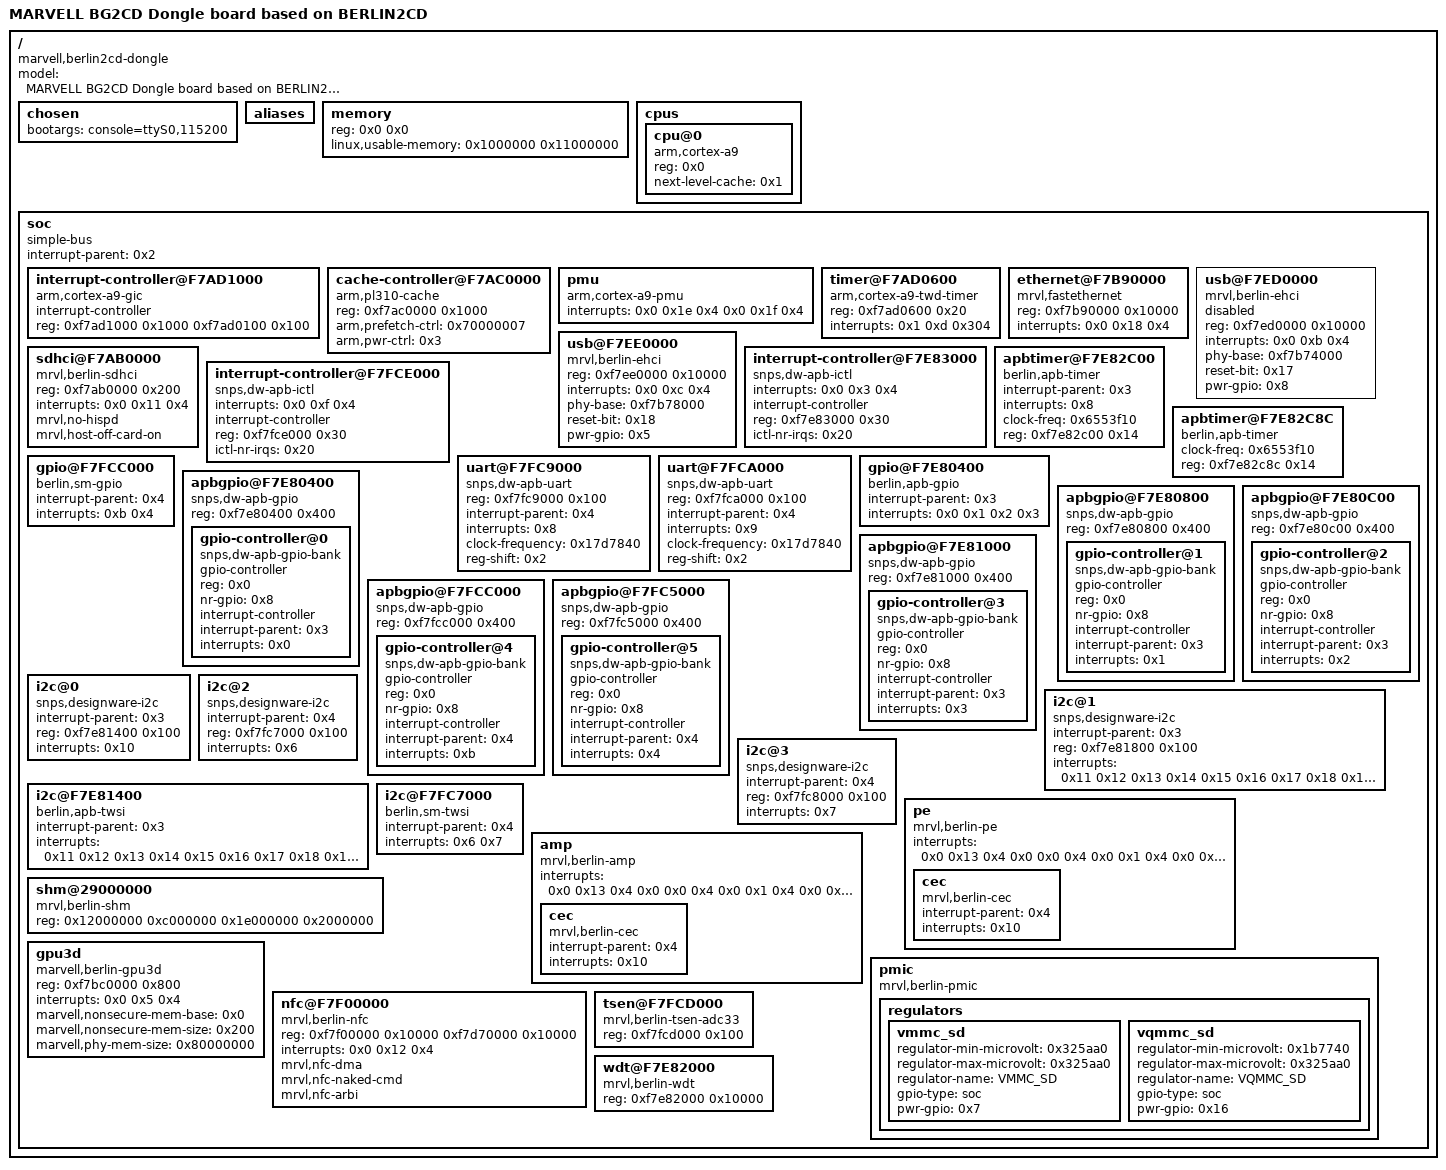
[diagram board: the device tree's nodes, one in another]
/dts-v1/;

/ {
	#address-cells = <0x1>;
	#size-cells = <0x1>;
	model = "MARVELL BG2CD Dongle board based on BERLIN2CD";
	compatible = "marvell,berlin2cd-dongle", "marvell,berlin2cd";

	chosen {
		bootargs = "console=ttyS0,115200";
	};

	aliases {
	};

	memory {
		device_type = "memory";
		reg = <0x0 0x0>;
		linux,usable-memory = <0x1000000 0x11000000>;
	};

	cpus {
		#address-cells = <0x1>;
		#size-cells = <0x0>;

		cpu@0 {
			device_type = "cpu";
			compatible = "arm,cortex-a9";
			reg = <0x0>;
			next-level-cache = <0x1>;
		};
	};

	soc {
		#address-cells = <0x1>;
		#size-cells = <0x1>;
		compatible = "simple-bus";
		interrupt-parent = <0x2>;
		ranges;

		interrupt-controller@F7AD1000 {
			compatible = "arm,cortex-a9-gic";
			#interrupt-cells = <0x3>;
			interrupt-controller;
			reg = <0xf7ad1000 0x1000 0xf7ad0100 0x100>;
			linux,phandle = <0x2>;
			phandle = <0x2>;
		};

		cache-controller@F7AC0000 {
			compatible = "arm,pl310-cache";
			reg = <0xf7ac0000 0x1000>;
			arm,prefetch-ctrl = <0x70000007>;
			arm,pwr-ctrl = <0x3>;
			linux,phandle = <0x1>;
			phandle = <0x1>;
		};

		pmu {
			compatible = "arm,cortex-a9-pmu";
			interrupts = <0x0 0x1e 0x4 0x0 0x1f 0x4>;
		};

		timer@F7AD0600 {
			compatible = "arm,cortex-a9-twd-timer";
			reg = <0xf7ad0600 0x20>;
			interrupts = <0x1 0xd 0x304>;
		};

		ethernet@F7B90000 {
			compatible = "mrvl,fastethernet";
			reg = <0xf7b90000 0x10000>;
			interrupts = <0x0 0x18 0x4>;
		};

		usb@F7ED0000 {
			compatible = "mrvl,berlin-ehci";
			reg = <0xf7ed0000 0x10000>;
			interrupts = <0x0 0xb 0x4>;
			phy-base = <0xf7b74000>;
			reset-bit = <0x17>;
			pwr-gpio = <0x8>;
			status = "disable";
		};

		usb@F7EE0000 {
			compatible = "mrvl,berlin-ehci";
			reg = <0xf7ee0000 0x10000>;
			interrupts = <0x0 0xc 0x4>;
			phy-base = <0xf7b78000>;
			reset-bit = <0x18>;
			pwr-gpio = <0x5>;
		};

		sdhci@F7AB0000 {
			compatible = "mrvl,berlin-sdhci";
			reg = <0xf7ab0000 0x200>;
			interrupts = <0x0 0x11 0x4>;
			mrvl,no-hispd;
			mrvl,host-off-card-on;
		};

		interrupt-controller@F7E83000 {
			compatible = "snps,dw-apb-ictl";
			interrupts = <0x0 0x3 0x4>;
			interrupt-controller;
			#interrupt-cells = <0x1>;
			reg = <0xf7e83000 0x30>;
			ictl-nr-irqs = <0x20>;
			linux,phandle = <0x3>;
			phandle = <0x3>;
		};

		interrupt-controller@F7FCE000 {
			compatible = "snps,dw-apb-ictl";
			interrupts = <0x0 0xf 0x4>;
			interrupt-controller;
			#interrupt-cells = <0x1>;
			reg = <0xf7fce000 0x30>;
			ictl-nr-irqs = <0x20>;
			linux,phandle = <0x4>;
			phandle = <0x4>;
		};

		apbtimer@F7E82C00 {
			compatible = "berlin,apb-timer";
			interrupt-parent = <0x3>;
			interrupts = <0x8>;
			clock-freq = <0x6553f10>;
			reg = <0xf7e82c00 0x14>;
		};

		apbtimer@F7E82C8C {
			compatible = "berlin,apb-timer";
			clock-freq = <0x6553f10>;
			reg = <0xf7e82c8c 0x14>;
		};

		uart@F7FC9000 {
			compatible = "snps,dw-apb-uart";
			reg = <0xf7fc9000 0x100>;
			interrupt-parent = <0x4>;
			interrupts = <0x8>;
			clock-frequency = <0x17d7840>;
			reg-shift = <0x2>;
		};

		uart@F7FCA000 {
			compatible = "snps,dw-apb-uart";
			reg = <0xf7fca000 0x100>;
			interrupt-parent = <0x4>;
			interrupts = <0x9>;
			clock-frequency = <0x17d7840>;
			reg-shift = <0x2>;
		};

		gpio@F7E80400 {
			compatible = "berlin,apb-gpio";
			interrupt-parent = <0x3>;
			interrupts = <0x0 0x1 0x2 0x3>;
		};

		gpio@F7FCC000 {
			compatible = "berlin,sm-gpio";
			interrupt-parent = <0x4>;
			interrupts = <0xb 0x4>;
		};

		apbgpio@F7E80400 {
			compatible = "snps,dw-apb-gpio";
			reg = <0xf7e80400 0x400>;
			#address-cells = <0x1>;
			#size-cells = <0x0>;

			gpio-controller@0 {
				compatible = "snps,dw-apb-gpio-bank";
				gpio-controller;
				reg = <0x0>;
				#gpio-cells = <0x2>;
				nr-gpio = <0x8>;
				interrupt-controller;
				#interrupt-cells = <0x2>;
				interrupt-parent = <0x3>;
				interrupts = <0x0>;
			};
		};

		apbgpio@F7E80800 {
			compatible = "snps,dw-apb-gpio";
			reg = <0xf7e80800 0x400>;
			#address-cells = <0x1>;
			#size-cells = <0x0>;

			gpio-controller@1 {
				compatible = "snps,dw-apb-gpio-bank";
				gpio-controller;
				reg = <0x0>;
				#gpio-cells = <0x2>;
				nr-gpio = <0x8>;
				interrupt-controller;
				#interrupt-cells = <0x2>;
				interrupt-parent = <0x3>;
				interrupts = <0x1>;
			};
		};

		apbgpio@F7E80C00 {
			compatible = "snps,dw-apb-gpio";
			reg = <0xf7e80c00 0x400>;
			#address-cells = <0x1>;
			#size-cells = <0x0>;

			gpio-controller@2 {
				compatible = "snps,dw-apb-gpio-bank";
				gpio-controller;
				reg = <0x0>;
				#gpio-cells = <0x2>;
				nr-gpio = <0x8>;
				interrupt-controller;
				#interrupt-cells = <0x2>;
				interrupt-parent = <0x3>;
				interrupts = <0x2>;
			};
		};

		apbgpio@F7E81000 {
			compatible = "snps,dw-apb-gpio";
			reg = <0xf7e81000 0x400>;
			#address-cells = <0x1>;
			#size-cells = <0x0>;

			gpio-controller@3 {
				compatible = "snps,dw-apb-gpio-bank";
				gpio-controller;
				reg = <0x0>;
				#gpio-cells = <0x2>;
				nr-gpio = <0x8>;
				interrupt-controller;
				#interrupt-cells = <0x2>;
				interrupt-parent = <0x3>;
				interrupts = <0x3>;
			};
		};

		apbgpio@F7FCC000 {
			compatible = "snps,dw-apb-gpio";
			reg = <0xf7fcc000 0x400>;
			#address-cells = <0x1>;
			#size-cells = <0x0>;

			gpio-controller@4 {
				compatible = "snps,dw-apb-gpio-bank";
				gpio-controller;
				reg = <0x0>;
				#gpio-cells = <0x2>;
				nr-gpio = <0x8>;
				interrupt-controller;
				#interrupt-cells = <0x2>;
				interrupt-parent = <0x4>;
				interrupts = <0xb>;
			};
		};

		apbgpio@F7FC5000 {
			compatible = "snps,dw-apb-gpio";
			reg = <0xf7fc5000 0x400>;
			#address-cells = <0x1>;
			#size-cells = <0x0>;

			gpio-controller@5 {
				compatible = "snps,dw-apb-gpio-bank";
				gpio-controller;
				reg = <0x0>;
				#gpio-cells = <0x2>;
				nr-gpio = <0x8>;
				interrupt-controller;
				#interrupt-cells = <0x2>;
				interrupt-parent = <0x4>;
				interrupts = <0x4>;
			};
		};

		i2c@0 {
			compatible = "snps,designware-i2c";
			interrupt-parent = <0x3>;
			reg = <0xf7e81400 0x100>;
			interrupts = <0x10>;
		};

		i2c@1 {
			compatible = "snps,designware-i2c";
			interrupt-parent = <0x3>;
			reg = <0xf7e81800 0x100>;
			interrupts = <0x11 0x12 0x13 0x14 0x15 0x16 0x17 0x18 0x19 0x1a 0x1b 0x1c>;
		};

		i2c@2 {
			compatible = "snps,designware-i2c";
			interrupt-parent = <0x4>;
			reg = <0xf7fc7000 0x100>;
			interrupts = <0x6>;
		};

		i2c@3 {
			compatible = "snps,designware-i2c";
			interrupt-parent = <0x4>;
			reg = <0xf7fc8000 0x100>;
			interrupts = <0x7>;
		};

		i2c@F7E81400 {
			compatible = "berlin,apb-twsi";
			interrupt-parent = <0x3>;
			interrupts = <0x11 0x12 0x13 0x14 0x15 0x16 0x17 0x18 0x19 0x1a 0x1b 0x1c 0x10>;
		};

		i2c@F7FC7000 {
			compatible = "berlin,sm-twsi";
			interrupt-parent = <0x4>;
			interrupts = <0x6 0x7>;
		};

		pe {
			compatible = "mrvl,berlin-pe";
			interrupts = <0x0 0x13 0x4 0x0 0x0 0x4 0x0 0x1 0x4 0x0 0x19 0x4 0x0 0x2 0x4>;

			cec {
				compatible = "mrvl,berlin-cec";
				interrupt-parent = <0x4>;
				interrupts = <0x10>;
			};
		};

		amp {
			compatible = "mrvl,berlin-amp";
			interrupts = <0x0 0x13 0x4 0x0 0x0 0x4 0x0 0x1 0x4 0x0 0x19 0x4 0x0 0x2 0x4>;

			cec {
				compatible = "mrvl,berlin-cec";
				interrupt-parent = <0x4>;
				interrupts = <0x10>;
			};
		};

		shm@29000000 {
			compatible = "mrvl,berlin-shm";
			reg = <0x12000000 0xc000000 0x1e000000 0x2000000>;
		};

		gpu3d {
			compatible = "marvell,berlin-gpu3d";
			reg = <0xf7bc0000 0x800>;
			interrupts = <0x0 0x5 0x4>;
			marvell,nonsecure-mem-base = <0x0>;
			marvell,nonsecure-mem-size = <0x200>;
			marvell,phy-mem-size = <0x80000000>;
		};

		pmic {
			compatible = "mrvl,berlin-pmic";

			regulators {

				vmmc_sd {
					regulator-min-microvolt = <0x325aa0>;
					regulator-max-microvolt = <0x325aa0>;
					regulator-name = "VMMC_SD";
					gpio-type = "soc";
					pwr-gpio = <0x7>;
				};

				vqmmc_sd {
					regulator-min-microvolt = <0x1b7740>;
					regulator-max-microvolt = <0x325aa0>;
					regulator-name = "VQMMC_SD";
					gpio-type = "soc";
					pwr-gpio = <0x16>;
				};
			};
		};

		nfc@F7F00000 {
			compatible = "mrvl,berlin-nfc";
			reg = <0xf7f00000 0x10000 0xf7d70000 0x10000>;
			interrupts = <0x0 0x12 0x4>;
			mrvl,nfc-dma;
			mrvl,nfc-naked-cmd;
			mrvl,nfc-arbi;
		};

		tsen@F7FCD000 {
			compatible = "mrvl,berlin-tsen-adc33";
			reg = <0xf7fcd000 0x100>;
		};

		wdt@F7E82000 {
			compatible = "mrvl,berlin-wdt";
			reg = <0xf7e82000 0x10000>;
		};
	};
};
